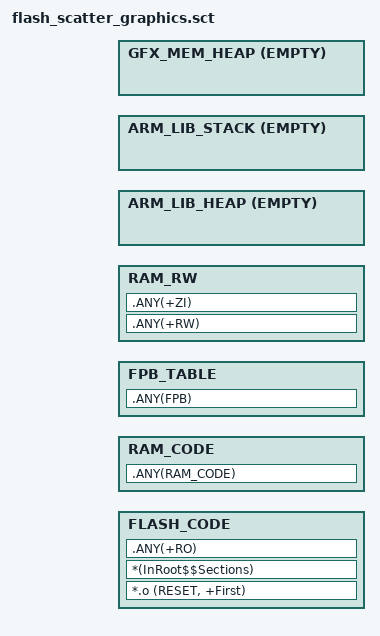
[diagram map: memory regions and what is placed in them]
#! armcc -E -I .\..\Src\user\ -I .\..\Src\config\ --cpu Cortex-M4

#include "flash_scatter_config.h"
#define ALIGN_DWORD 0x0008
#define ALIGN_WORD  0x0004
#define ALIGN_16KB  0x4000
#define ALIGN_32KB  0x8000

; *************************************************************
; *** Scatter-Loading Description File generated by uVision ***
; *************************************************************
;
; If an application uses a different memory layout then it must
; use a customized scatter file.
;**************************************************************

LR_FLASH APP_CODE_RUN_ADDR FLASH_SIZE {

    ; Flash AREA
    FLASH_CODE APP_CODE_RUN_ADDR APP_MAX_CODE_SIZE {  ; load address = execution address
        *.o (RESET, +First)
        *(InRoot$$Sections)
        .ANY(+RO)
      }

    ; Ram code space AREA
    RAM_CODE (RAM_CODE_SPACE_START) RAM_CODE_SPACE_SIZE {
        .ANY(RAM_CODE)
    }

    ; FPB space
    FPB_TABLE (FPB_DATA_SPACE_START) FPB_DATA_SPACE_SIZE {
        .ANY(FPB)
    }

    ; Ram data
    RAM_RW (+0) APP_RAM_SIZE {
        .ANY(+RW)
        .ANY(+ZI)
    }

    ; Ram heap
    ARM_LIB_HEAP  AlignExpr(+0, ALIGN_DWORD) EMPTY SYSTEM_HEAP_SIZE {}
    ; Ram stack
    ARM_LIB_STACK AlignExpr(+0, ALIGN_DWORD) EMPTY SYSTEM_STACK_SIZE {}

    ; ASSERT the RAM used address smaller the sram end address
    ScatterAssert(ImageBase(ARM_LIB_STACK) < 0x20080000)

    ; GRAPHICS Memory space AREA
    ; Notice 0x20880000 is the PSRAM end address
    GFX_MEM_HEAP AlignExpr(+0x10000000, ALIGN_DWORD) EMPTY (0x20880000 - ImageLimit(ARM_LIB_STACK)) {
        ;*(GRAPH_MEM)
    }
}
